AUTOSAR XML (schema 00049)
package /Application/DltConfig
  dlt log channel to process mapping DltLogChannelToProcessMapping_SubscriptionManager_TO_SubscriptionManager: dlt-log-channel=SubscriptionManager, process=SubscriptionManager
package /Application/Executable
  executable SubscriptionManager: category=APPLICATION_LEVEL, logging-behavior=USES-LOGGING, reporting-behavior=REPORTS-EXECUTION-STATE, version=1.0.0
    root sw component prototype AA: application-type=SubscriptionManager
package /Application/Manifest
  service instance to port prototype mapping SubscriptionManager_AA_PPortSubscriptionManagement: port-prototype=AA.PPortSubscriptionManagement, service-instance=EEVP_SubscriptionManager_Provider_SubscriptionManagement
  service instance to port prototype mapping SubscriptionManager_AA_RPortOtaSubscription: port-prototype=AA.RPortOtaSubscription, service-instance=EEVP_SubscriptionManager_Consumer_OtaSubscription
package /Application/Process
  process SubscriptionManager: executable=SubscriptionManager, state-dependent-startup-config{execution-dependency=OTAClient.Running, function-group-state=MachineFG.Startup, resource-group=DefaultResourceGroup, startup-config=SubscriptionManager}
    process state machine SubscriptionManager: type=ProcessState
package /Application/StartupConfig
  startup config set EEVP_SubscriptionManager_StartupConfig
    startup config SubscriptionManager: scheduling-policy=SCHED_OTHER, scheduling-priority=0, timeout={enter-timeout-value=2.0, exit-timeout-value=2.0}
package /Application/SwComponent
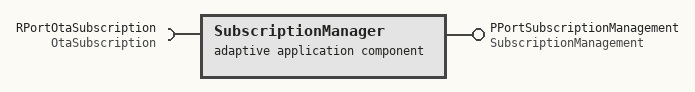
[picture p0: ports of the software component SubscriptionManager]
  adaptive application sw component type SubscriptionManager
    provide port PPortSubscriptionManagement: provided-interface=SubscriptionManagement
    require port RPortOtaSubscription: required-interface=OtaSubscription
